# WB32F10x register map
File version: 1.2
CPU: CM3 r2p0, little endian, MPU, no FPU, 4 interrupt priority bits
Registers are 32-bit, read-write, reset 0x0 unless marked. A register's access mark holds for its fields unless they carry their own. Offsets are from the block's base; [hi:lo] are bit positions.

## EXTI — Interrupt/event controller
Base 0x40001800
0x00 INTEN — Interrupt enable register
  [18:0] MRx — Interrupt enable Bits
0x04 EMR — Event enable register
  [18:0] MRx — Event enable Bits
0x08 RTSR — Rising edge trigger enable register
  [18:0] TRx — Rising edge trigger enable
0x0C FTSR — Falling edge trigger enable register
  [18:0] TRx — Falling edge trigger enable
0x10 SWIER — Software interrupt event register
  [18:0] SWIERx — Interrupt/Event software trigger
0x14 PR reset not defined — Pending register
  [18:0] PRx — Interrupt pending status

## ANCTL — Analog control
Base 0x40010400
0x1C BGCR2 — BG control SFR2
  [1] TEMPOUTEN — Bandgap temperature sensor output enable
0x2C MHSIENR reset 0x1 — MHSI enable SFR
  [0] MHSION — Internal MHSI enable
0x30 MHSISR ro reset 0x1 — MHSI enable SFR
  [0] MHSIRDY — Internal MHSI output status
0x38 FHSIENR reset 0x1 — FHSI enable SFR
  [0] FHSION — Internal FHSI enable control
0x3C FHSISR ro reset 0x1 — FHSI Status SFR
  [0] FHSIRDY — Internal FHSI clock output status
0x44 LSIENR — LSI enable SFR
  [0] LSION — Internal LSI enable
0x48 LSISR ro — LSI Status SFR
  [0] LSIRDY — Internal LSI clock output Status
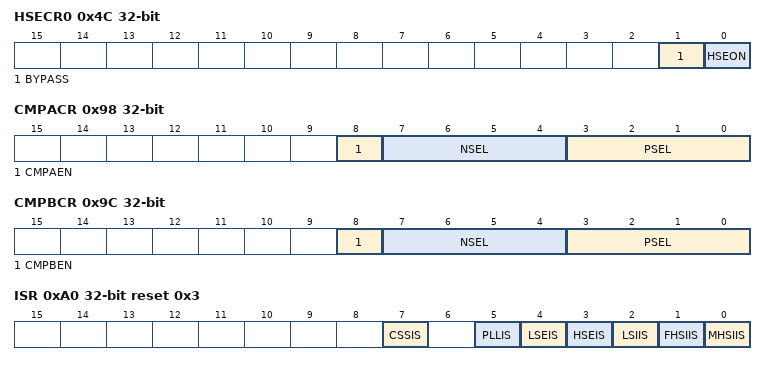
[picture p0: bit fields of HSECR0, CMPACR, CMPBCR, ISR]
0x4C HSECR0 — HSE control SFR 0
  [1] BYPASS — External clock input mode enable
  [0] HSEON — HSE enable
0x50 HSECR1 — HSE control SFR 1
  [1] PADOEN — HSE clock loop back from PAD
0x58 HSESR ro — HSE Status SFR
  [0] HSERDY — HSE clock output Status
0x74 PLLCR — PLL control SFR
  [7:6] PLLMUL — PLL multiplier factor
0x78 PLLENR — PLL enable control
  [0] PLLON
0x7C PLLSR ro — PLL Status SFR
  [1:0] PLLRDY — PLL clock output Status
0x80 PVDCR reset 0x4 — PVD control SFR
  [2:0] PLS — PVD threshold voltage selection
0x84 PVDENR — PVD enable SFR
  [0] PVDE — PVD enable control
0x8C SARENR reset 0x1E — SARADC enable SFR
  [0] SAREN — SARADC enable control
0x94 PORCR reset 0x841 — POR control SFR
  [11:0] POREN — POR enable control
0x98 CMPACR — CMPA control SFR
  [8] CMPAEN — CMPA enable control
  [7:4] NSEL — CMPA negative input channel selection
  [3:0] PSEL — CMPA positive input channel selection
0x9C CMPBCR — CMPB control SFR
  [8] CMPBEN — CMPB enable control
  [7:4] NSEL — CMPB negative input channel selection
  [3:0] PSEL — CMPB positive input channel selection
0xA0 ISR ro reset 0x3 — INT Status SFR
  [7] CSSIS — HSE clock failure detection interrupt flag
  [5] PLLIS — PLL clock output stable flag
  [4] LSEIS — LSE clock output stable flag
  [3] HSEIS — HSE clock output stable flag
  [2] LSIIS — LSI clock output stable flag
  [1] FHSIIS — FHSI clock output stable flag
  [0] MHSIIS — MHSI clock output stable flag
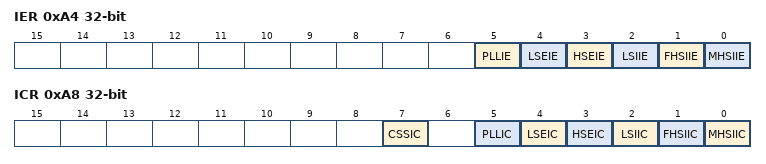
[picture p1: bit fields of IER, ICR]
0xA4 IER — INT enable SFR
  [5] PLLIE — PLL clock stable interrupt enable
  [4] LSEIE — LSE clock stable interrupt enable
  [3] HSEIE — HSE clock stable interrupt enable
  [2] LSIIE — LSI clock stable interrupt enable
  [1] FHSIIE — FHSI clock stable interrupt enable
  [0] MHSIIE — MHSI clock stable interrupt enable
0xA8 ICR — INT clear SFR
  [7] CSSIC — clear HSE clock failure detection interrupt flag
  [5] PLLIC — clear PLL clock output stable interrupt flag
  [4] LSEIC — clear LSE clock output stable interrupt flag
  [3] HSEIC — clear HSE clock output stable interrupt flag
  [2] LSIIC — clear LSI clock output stable interrupt flag
  [1] FHSIIC — clear FHSI clock output stable interrupt flag
  [0] MHSIIC — clear MHSI clock output stable interrupt flag
0xAC CMPASR ro — CMPA Status SFR
  [0] CMPAOUT — CMPA comparison result
0xB0 CMPBSR ro — CMPB Status SFR
  [0] CMPBOUT — CMPB comparison result
0xB4 CSSENR — CSS enable SFR
  [0] CSSON — HSE clock failure detection control
0xB8 CSSCR — CSS configuration SFR
  [11:0] FREQCNT — Configure CSS count value, must be configured to 0x03
